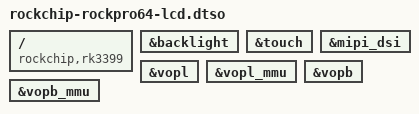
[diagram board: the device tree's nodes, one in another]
//For RockPro64 7″ LCD TOUCH SCREEN PANEL

/dts-v1/;
/plugin/;

/ {
  compatible = "rockchip,rk3399";
};

&backlight {
  status = "okay";
};

&touch {
  status = "okay";
};

&mipi_dsi {
  status = "okay";
};

&vopl {
  status = "okay";
};

&vopl_mmu {
  status = "okay";
};

&vopb {
  status = "okay";
};

&vopb_mmu {
  status = "okay";
};
